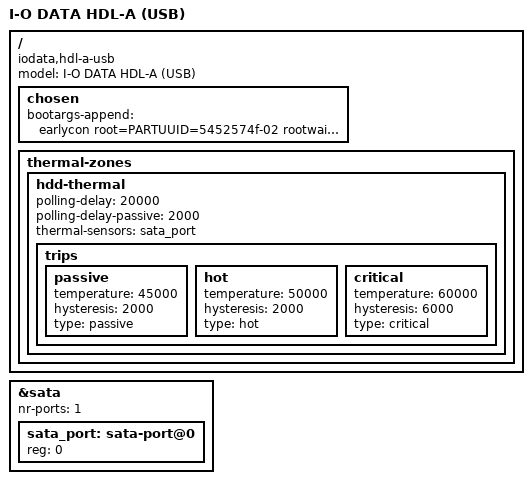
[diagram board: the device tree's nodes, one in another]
// SPDX-License-Identifier: GPL-2.0-or-later OR MIT

#include "kirkwood-hdlx-a.dtsi"

/ {
	model = "I-O DATA HDL-A (USB)";
	compatible = "iodata,hdl-a-usb", "marvell,kirkwood-88f6282", "marvell,kirkwood";

	chosen {
		/*
		 * Kernel and rootfs are stored to the storage connected to the
		 * SATA port (port1) or USB port.
		 * The path to the partition (/dev/sdXN) which contains rootfs
		 * data will be assigned dynamically, so GPT partition UUID or
		 * MSDOS signature is required instead.
		 */
		bootargs-append = " earlycon root=PARTUUID=5452574f-02 rootwait=20";
	};

	thermal-zones {
		hdd-thermal {
			polling-delay = <20000>;
			polling-delay-passive = <2000>;

			thermal-sensors = <&sata_port>;

			trips {
				passive {
					temperature = <45000>;
					hysteresis = <2000>;
					type = "passive";
				};

				hot {
					temperature = <50000>;
					hysteresis = <2000>;
					type = "hot";
				};

				critical {
					temperature = <60000>;
					hysteresis = <6000>;
					type = "critical";
				};
			};
		};
	};
};

&sata {
	status = "okay";
	nr-ports = <1>;
	#address-cells = <1>;
	#size-cells = <0>;

	sata_port: sata-port@0 {
		reg = <0>;
		#thermal-sensor-cells = <0>;
	};
};
